VERSION ""

NS_ :

BS_:

BU_: AEM_EMS_4 DATALOGGER DATALOGGER_2 DATALOGGER_19

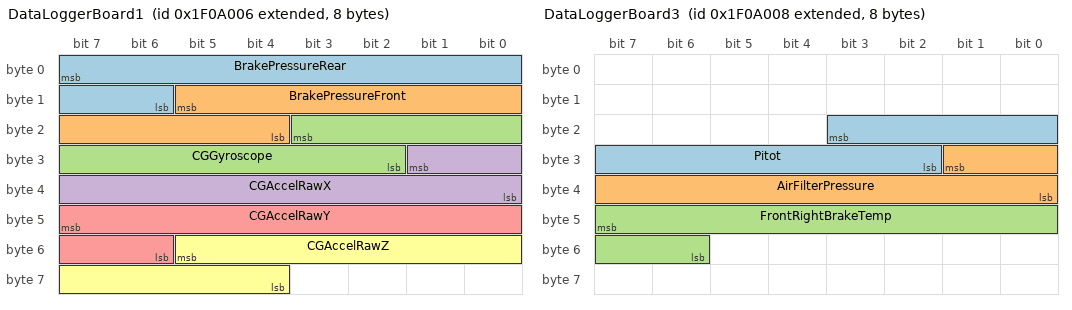
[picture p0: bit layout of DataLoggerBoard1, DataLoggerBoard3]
BO_ 2180030470 DataLoggerBoard1: 8 DATALOGGER_19
 SG_ BrakePressureRear : 7|10@0+ (0.9775171065,0) [0|1000] "pressure:psi" Vector__XXX
 SG_ BrakePressureFront : 13|10@0+ (0.9775171065,0) [0|1000] "pressure:psi" Vector__XXX
 SG_ CGGyroscope : 19|10@0+ (0.12201,-63.1553) [-50|50] "rotation:deg/s" Vector_XXX
 SG_ CGAccelRawX : 25|10@0+ (0.012219,-6.215) [-5|5] "acceleration:G" Vector__XXX
 SG_ CGAccelRawY : 47|10@0+ (0.012219,-6.215) [-5|5] "acceleration:G" Vector__XXX
 SG_ CGAccelRawZ : 53|10@0+ (0.012219,-6.215) [-5|5] "acceleration:G" Vector__XXX

BO_ 2180030471 DataLoggerBoard2: 8 DATALOGGER_19
 SG_ WheelSpeed1 : 7|10@0+ (1.0,0) [0|1023] "angular_speed:rpm" Vector__XXX
 SG_ WheelSpeed2 : 13|10@0+ (1.0,0) [0|1023] "angular_speed:rpm" Vector__XXX

BO_ 2180030472 DataLoggerBoard3: 8 DATALOGGER_19
 SG_ Pitot : 19|10@0+ (0.01527370479,-7.6368523949) [0|12.5] "pressure:mbar" Vector_XXX
 SG_ AirFilterPressure : 25|10@0+ (1.57702E-003,0) [0|101.325] "pressure:kPa" Vector__XXX
 SG_ FrontRightBrakeTemp : 47|10@0+ (0.977517,-97.7517) [0|800] "temperature:C" Vector__XXX

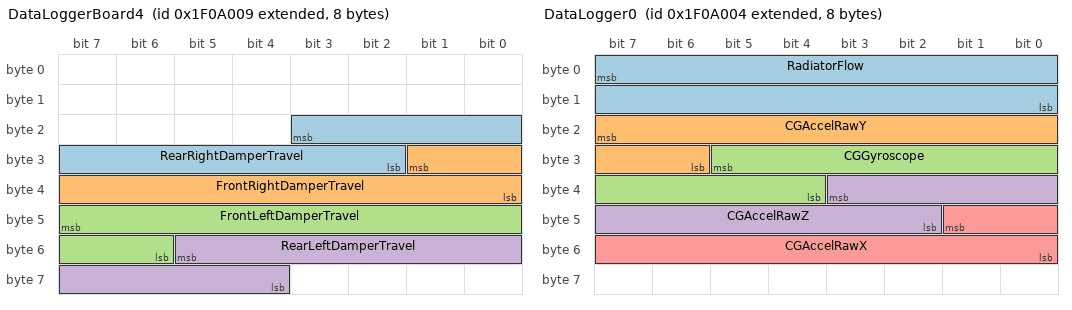
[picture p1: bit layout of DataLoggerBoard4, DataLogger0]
BO_ 2180030473 DataLoggerBoard4: 8 DATALOGGER_19
 SG_ RearRightDamperTravel : 19|10@0+ (0.048876,0) [0|50] "distance:mm" Vector_XXX
 SG_ FrontRightDamperTravel : 25|10@0+ (0.048876,0) [0|50] "distance:mm" Vector__XXX
 SG_ FrontLeftDamperTravel : 47|10@0+ (0.048876,0) [0|50] "distance:mm" Vector__XXX
 SG_ RearLeftDamperTravel : 53|10@0+ (0.048876,0) [0|50] "distance:mm" Vector__XXX

BO_ 2180030469 DataLogger1: 8 DATALOGGER_2
 SG_ WheelCounts1 : 7|16@0+ (1.0,0) [0|65535] "unitless:" Vector_XXX
 SG_ WheelCounts2 : 23|16@0+ (1.0,0) [0|65535] "unitless:" Vector_XXX

BO_ 2180030468 DataLogger0: 8 DATALOGGER
 SG_ RadiatorFlow : 7|16@0+ (1.8181818,0) [0|119154.545455] "flow:L/min" Vector_XXX
 SG_ CGAccelRawY : 23|10@0+ (0.012219,-6.215) [-5|5] "acceleration:G" Vector__XXX
 SG_ CGGyroscope : 29|10@0+ (0.12201,-63.1553) [-50|50] "rotation:deg/s" Vector_XXX
 SG_ CGAccelRawZ : 35|10@0+ (0.012219,-6.215) [-5|5] "acceleration:G" Vector__XXX
 SG_ CGAccelRawX : 41|10@0+ (0.012219,-6.215) [-5|5] "acceleration:G" Vector__XXX

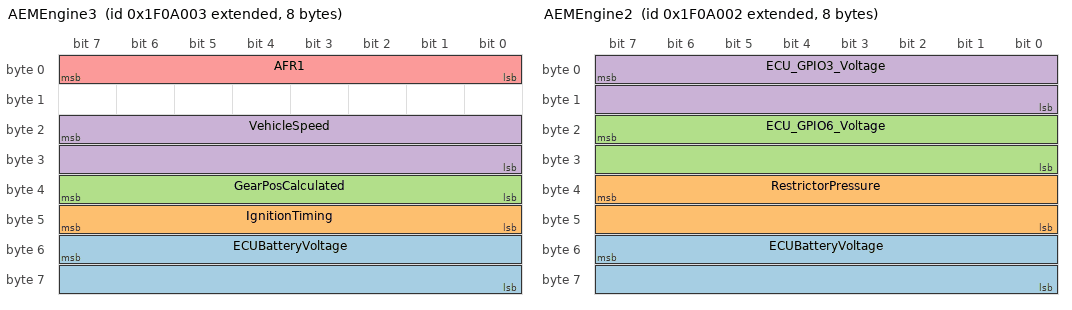
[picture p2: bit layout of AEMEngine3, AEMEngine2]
BO_ 2180030467 AEMEngine3: 8 AEM_EMS_4
 SG_ ECUBatteryVoltage : 55|16@0+ (0.0002455,0) [0|16.089] "voltage:V" Vector__XXX
 SG_ IgnitionTiming : 47|8@0+ (0.35156,-17) [-17|72.65] "angle:deg" Vector__XXX
 SG_ GearPosCalculated : 39|8@0+ (1,0) [0|255] "unitless:" Vector__XXX
 SG_ VehicleSpeed : 23|16@0+ (0.00390625,0) [0|255.99609375] "speed:mph" Vector__XXX
 SG_ AFR1 : 7|8@0+ (0.057227,7.325) [7.325|21.917885] "afr:AFR Gasoline" Vector__XXX

BO_ 2180030466 AEMEngine2: 8 AEM_EMS_4
 SG_ ECUBatteryVoltage : 55|16@0+ (0.000326,0) [0|21.36441] "voltage:V" Vector__XXX
 SG_ RestrictorPressure : 39|16@0+ (1.57702E-003,0) [0|101.325] "pressure:kPa" Vector__XXX
 SG_ ECU_GPIO6_Voltage : 23|16@0+ (7.782E-005,0) [0|5.0999] "voltage:V" Vector__XXX
 SG_ ECU_GPIO3_Voltage : 7|16@0+ (7.782E-005,0) [0|5.0999] "voltage:V" Vector__XXX

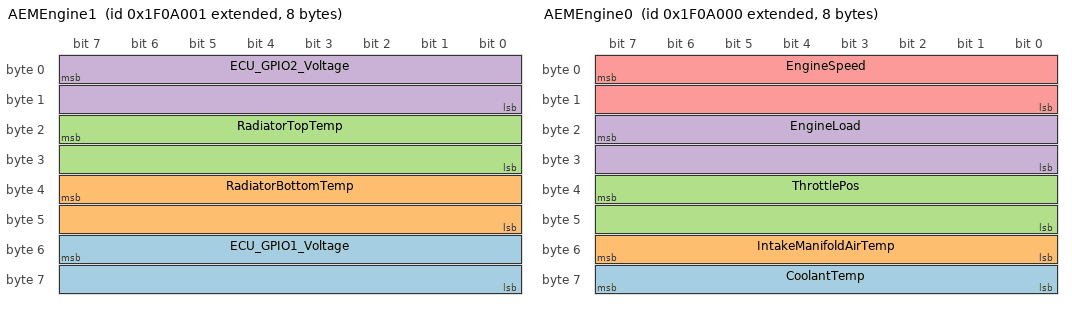
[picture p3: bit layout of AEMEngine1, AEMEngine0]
BO_ 2180030465 AEMEngine1: 8 AEM_EMS_4
 SG_ ECU_GPIO1_Voltage : 55|16@0+ (7.782E-005,0) [0|5.0999] "voltage:V" Vector__XXX
 SG_ RadiatorBottomTemp : 39|16@0+ (-1.02997E-002,380.485294) [-58|302] "temperature:F" Vector__XXX
 SG_ RadiatorTopTemp : 23|16@0+ (-1.02997E-002,380.485294) [-58|302] "temperature:F" Vector__XXX
 SG_ ECU_GPIO2_Voltage : 7|16@0+ (7.782E-005,0) [0|5.0999] "voltage:V" Vector__XXX

BO_ 2180030464 AEMEngine0: 8 AEM_EMS_4
 SG_ CoolantTemp : 63|8@0- (1.8,32) [-198.4|260.6] "temperature:F" Vector__XXX
 SG_ IntakeManifoldAirTemp : 55|8@0- (1.8,32) [-198.4|260.6] "temperature:F" Vector__XXX
 SG_ ThrottlePos : 39|16@0+ (0.0015259,0) [0|99.9998565] "fraction:%" Vector__XXX
 SG_ EngineLoad : 23|16@0+ (0.0015259,0) [0|99.998565] "fraction:%" Vector__XXX
 SG_ EngineSpeed : 7|16@0+ (0.39063,0) [0|25599.94] "angular_speed:rpm" Vector__XXX

BA_DEF_ BO_  "GenMsgSendType" STRING ;
BA_DEF_  "ProtocolType" STRING ;
BA_DEF_  "NmType" STRING ;
BA_DEF_ BO_  "GenMsgCycleTime" INT 1 10000;
BA_DEF_ BO_  "GenMsgILSupport" ENUM  "No","Yes";
BA_DEF_ BU_  "ILUsed" ENUM  "No","Yes";
BA_DEF_  "VersionNumber" INT 0 10000;
BA_DEF_  "VersionDay" INT 1 31;
BA_DEF_  "VersionMonth" INT 1 12;
BA_DEF_  "VersionYear" INT 2016 3000;
BA_DEF_  "BusType" STRING ;
BA_DEF_ BO_  "DBC_Author_Contact" STRING ;
BA_DEF_DEF_  "DBC_Author_Contact" "CANbusInfo@AEMelectronics.com";
BA_DEF_DEF_  "GenMsgSendType" "Cyclic";
BA_DEF_DEF_  "ProtocolType" "";
BA_DEF_DEF_  "NmType" "";
BA_DEF_DEF_  "GenMsgCycleTime" 20;
BA_DEF_DEF_  "GenMsgILSupport" "Yes";
BA_DEF_DEF_  "ILUsed" "Yes";
BA_DEF_DEF_  "VersionNumber" 0;
BA_DEF_DEF_  "VersionDay" 1;
BA_DEF_DEF_  "VersionMonth" 1;
BA_DEF_DEF_  "VersionYear" 2016;
BA_DEF_DEF_  "BusType" "Can";
BA_ "ProtocolType" "AEM Net";
BA_ "NmType" "AEM Net";
BA_ "VersionNumber" 3;
BA_ "VersionDay" 28;
BA_ "VersionMonth" 11;
BA_ "BusType" "CAN";
BA_ "GenMsgCycleTime" BO_ 2180030470 50;
BA_ "GenMsgCycleTime" BO_ 2180030466 16;
BA_ "GenMsgCycleTime" BO_ 2180030465 16;
BA_ "GenMsgCycleTime" BO_ 2180030464 16;
